# SAMA7G54D1GN2 register map
Vendor: Microchip Technology; Series: SAMA7G5; File version: 0
Registers are 32-bit, read-write, reset 0x0 unless marked. A register's access mark holds for its fields unless they carry their own. Offsets are from the block's base; [hi:lo] are bit positions; lines under a group give offsets from that group; {n}, {i} and the like mark numbered series; 'fields as' and 'values as' point back to an identical list.

## UDPHSA — IP_Name
Base 0xE0814000; register names take the prefix UDPHS_
Same registers: UDPHSB 0xE0818000
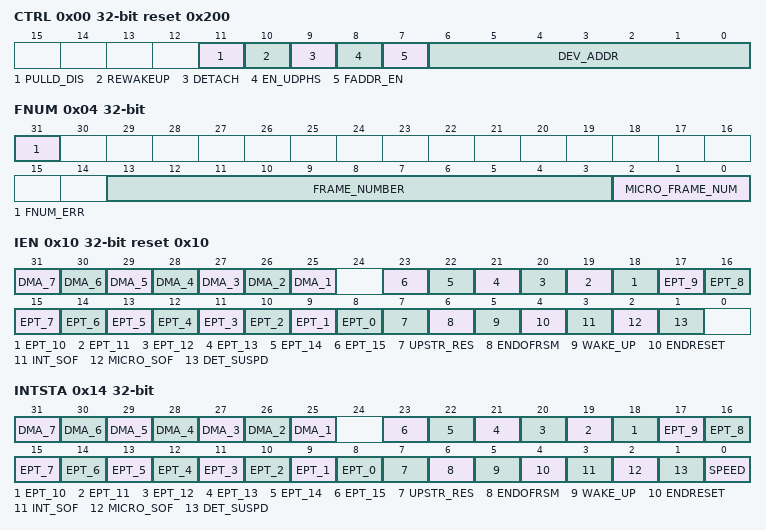
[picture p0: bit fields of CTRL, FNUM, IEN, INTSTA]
0x00 CTRL reset 0x200 — UDPHS Control Register
  [11] PULLD_DIS — Pulldown Disable (cleared upon USB reset)
  [10] REWAKEUP — Send Remote Wake-up (cleared upon USB reset)
    0=Remote Wake-up is disabled (read), or this bit has no effect (write); 1=Remote Wake-up is enabled (read), or this bit forces an external interrupt on the UDPHS controller for Remote Wake-up purposes
  [9] DETACH — Detach Command
    0=UDPHS is attached (read), or this bit pulls up the DP line (attach command) (write); 1=UDPHS is detached, UTMI transceiver is suspended (read), or this bit simulates a detach on the UDPHS line and forces the UTMI transceiver into Suspend state (Suspend M = 0) (write)
  [8] EN_UDPHS — UDPHS Enable
    0=UDPHS is disabled (read), or this bit disables and resets the UDPHS controller (write). Switch the UHPHS to UTMI.; 1=UDPHS is enabled (read), or this bit enables the UDPHS controller (write). Switch the UDPHS to UTMI.
  [7] FADDR_EN — Function Address Enable (cleared upon USB reset)
    0=The device is not in Address state (read), or only the default function address is used (write); 1=The device is in Address state (read), or this bit is set by the device firmware after a successful status phase of a SET_ADDRESS transaction (write). When set, the only address accepted by the UDPHS controller is the one stored in the UDPHS Address field. It will not be cleared afterwards by the device firmware. It is cleared by hardware on hardware reset, or when UDPHS bus reset is received.
  [6:0] DEV_ADDR — UDPHS Address (cleared upon USB reset)
0x04 FNUM ro — UDPHS Frame Number Register
  [31] FNUM_ERR — Frame Number CRC Error (cleared upon USB reset)
  [13:3] FRAME_NUMBER — Frame Number as defined in the Packet Field Formats (cleared upon USB reset)
  [2:0] MICRO_FRAME_NUM — Microframe Number (cleared upon USB reset)
0x10 IEN reset 0x10 — UDPHS Interrupt Enable Register
  [n+24] DMA_{n} (n=1..7) — DMA Channel {n} Interrupt Enable (cleared upon USB reset)
    0=Disable the interrupts for this channel; 1=Enable the interrupts for this channel
  [n+8] EPT_{n} (n=0..15) — Endpoint {n} Interrupt Enable (cleared upon USB reset)
    0=Disable the interrupts for this endpoint; 1=Enable the interrupts for this endpoint
  [7] UPSTR_RES — Upstream Resume Interrupt Enable (cleared upon USB reset)
    0=Disable Upstream Resume Interrupt; 1=Enable Upstream Resume Interrupt
  [6] ENDOFRSM — End Of Resume Interrupt Enable (cleared upon USB reset)
    0=Disable Resume Interrupt; 1=Enable Resume Interrupt
  [5] WAKE_UP — Wake Up CPU Interrupt Enable (cleared upon USB reset)
    0=Disable Wake-up CPU Interrupt; 1=Enable Wake-up CPU Interrupt
  [4] ENDRESET — End Of Reset Interrupt Enable (cleared upon USB reset)
    0=Disable End Of Reset Interrupt; 1=Enable End Of Reset Interrupt. Automatically enabled after USB reset.
  [3] INT_SOF — SOF Interrupt Enable (cleared upon USB reset)
    0=Disable SOF Interrupt; 1=Enable SOF Interrupt
  [2] MICRO_SOF — Micro-SOF Interrupt Enable (cleared upon USB reset)
    0=Disable Micro-SOF Interrupt; 1=Enable Micro-SOF Interrupt
  [1] DET_SUSPD — Suspend Interrupt Enable (cleared upon USB reset)
    0=Disable Suspend Interrupt; 1=Enable Suspend Interrupt
0x14 INTSTA ro — UDPHS Interrupt Status Register
  [n+24] DMA_{n} (n=1..7) — DMA Channel {n} Interrupt
    0=Reset when the UDPHS_DMASTATUSx interrupt source is cleared; 1=Set by hardware when an interrupt is triggered by the DMA Channelx and this endpoint interrupt is enabled by the DMA_x bit in UDPHS_IEN
  [n+8] EPT_{n} (n=0..15) — Endpoint {n} Interrupt (cleared upon USB reset)
    0=Reset when the UDPHS_EPTSTAx interrupt source is cleared; 1=Set by hardware when an interrupt is triggered by the UDPHS_EPTSTAx register and this endpoint interrupt is enabled by the EPT_x bit in UDPHS_IEN
  [7] UPSTR_RES — Upstream Resume Interrupt
    0=Cleared by setting the UPSTR_RES bit in UDPHS_CLRINT; 1=Set by hardware when the UDPHS controller is sending a resume signal called 'upstream resume'. This triggers a UDPHS interrupt when the UPSTR_RES bit is set in UDPHS_IEN.
  [6] ENDOFRSM — End Of Resume Interrupt
    0=Cleared by setting the ENDOFRSM bit in UDPHS_CLRINT; 1=Set by hardware when the UDPHS controller detects a good end of resume signal initiated by the host. This triggers a UDPHS interrupt when the ENDOFRSM bit is set in UDPHS_IEN.
  [5] WAKE_UP — Wake Up CPU Interrupt
    0=Cleared by setting the WAKE_UP bit in UDPHS_CLRINT; 1=Set by hardware when the UDPHS controller is in SUSPEND state and is re-activated by a filtered non-idle signal from the UDPHS line (not by an upstream resume). This triggers a UDPHS interrupt when the WAKE_UP bit is set in UDPHS_IEN register. When receiving this interrupt, the user has to enable the device controller clock prior to operation.
  [4] ENDRESET — End Of Reset Interrupt
    0=Cleared by setting the ENDRESET bit in UDPHS_CLRINT; 1=Set by hardware when an End Of Reset has been detected by the UDPHS controller. This triggers a UDPHS interrupt when the ENDRESET bit is set in UDPHS_IEN.
  [3] INT_SOF — Start Of Frame Interrupt
    0=Cleared by setting the INT_SOF bit in UDPHS_CLRINT; 1=Set by hardware when an UDPHS Start Of Frame PID (SOF) has been detected (every 1 ms) or synthesized by UDPHS. This triggers a UDPHS interrupt when the INT_SOF bit is set in UDPHS_IEN register. In case of detected SOF, in High Speed mode, the MICRO_FRAME_NUMBER field is cleared in UDPHS_FNUM register and the FRAME_NUMBER field is updated.
  [2] MICRO_SOF — Micro Start Of Frame Interrupt
    0=Cleared by setting the MICRO_SOF bit in UDPHS_CLRINT register; 1=Set by hardware when an UDPHS micro start of frame PID (SOF) has been detected (every 125 us) or synthesized by UDPHS. This triggers a UDPHS interrupt when the MICRO_SOF bit is set in UDPHS_IEN. In case of detected SOF, the MICRO_FRAME_NUM field in UDPHS_FNUM register is incremented and the FRAME_NUMBER field does not change.
  [1] DET_SUSPD — Suspend Interrupt
    0=Cleared by setting the DET_SUSPD bit in UDPHS_CLRINT register; 1=Set by hardware when a UDPHS Suspend (Idle bus for three frame periods, a J state for 3 ms) is detected. This triggers a UDPHS interrupt when the DET_SUSPD bit is set in UDPHS_IEN register.
  [0] SPEED — Speed Status
    0=Reset by hardware when the hardware is in Full Speed mode; 1=Set by hardware when the hardware is in High Speed mode
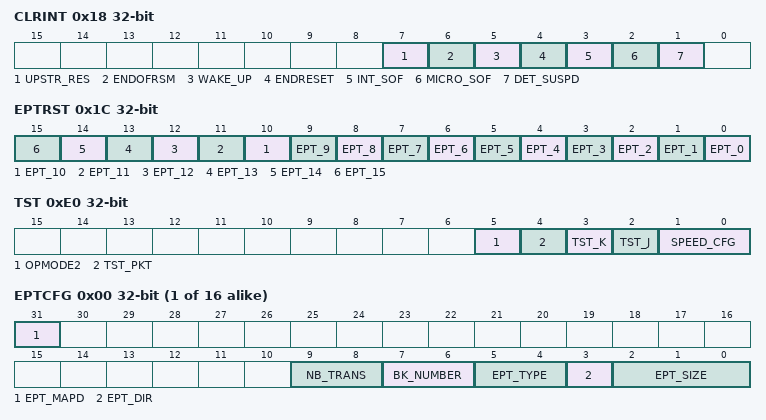
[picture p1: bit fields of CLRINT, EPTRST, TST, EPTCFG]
0x18 CLRINT wo — UDPHS Clear Interrupt Register
  [7] UPSTR_RES — Upstream Resume Interrupt Clear
    0=No effect; 1=Clear the UPSTR_RES bit in UDPHS_INTSTA
  [6] ENDOFRSM — End Of Resume Interrupt Clear
    0=No effect; 1=Clear the ENDOFRSM bit in UDPHS_INTSTA
  [5] WAKE_UP — Wake Up CPU Interrupt Clear
    0=No effect; 1=Clear the WAKE_UP bit in UDPHS_INTSTA
  [4] ENDRESET — End Of Reset Interrupt Clear
    0=No effect; 1=Clear the ENDRESET bit in UDPHS_INTSTA
  [3] INT_SOF — Start Of Frame Interrupt Clear
    0=No effect; 1=Clear the INT_SOF bit in UDPHS_INTSTA
  [2] MICRO_SOF — Micro Start Of Frame Interrupt Clear
    0=No effect; 1=Clear the MICRO_SOF bit in UDPHS_INTSTA
  [1] DET_SUSPD — Suspend Interrupt Clear
    0=No effect; 1=Clear the DET_SUSPD bit in UDPHS_INTSTA
0x1C EPTRST wo — UDPHS Endpoints Reset Register
  [all] fields
    0=No effect; 1=Reset the Endpointx state
  [n] EPT_{n} (n=0..15) — Endpoint {n} Reset
0xE0 TST — UDPHS Test Register
  [5] OPMODE2
    0=No effect; 1=Set to force the OpMode signal (UTMI interface) to '10', to disable the bit-stuffing and the NRZI encoding
  [4] TST_PKT — Test Packet Mode
    0=No effect; 1=Set to repetitively transmit the packet stored in the current bank. This enables the testing of rise and fall times, eye patterns, jitter, and any other dynamic waveform specifications.
  [3] TST_K — Test K Mode
    0=No effect; 1=Set to send the K state on the UDPHS line. This enables the testing of the high output drive level on the D- line.
  [2] TST_J — Test J Mode
    0=No effect; 1=Set to send the J state on the UDPHS line. This enables the testing of the high output drive level on the D+ line.
  [1:0] SPEED_CFG — Speed Configuration
    0=NORMAL (Normal mode: UDPHS is in Full Speed mode, ready to make a High Speed identification, if the host supports it and then to automatically switch to High Speed mode.); 2=HIGH_SPEED (Force High Speed: Set this value to force the hardware to work in High Speed mode. Only for debug or test purpose.); 3=FULL_SPEED (Force Full Speed: Set this value to force the hardware to work only in Full Speed mode. In this configuration, UDPHS will not respond to a High Speed reset handshake.)
{0x100+0x20*i} UDPHS_EPT[{i}] (i=0..15) group
  0x00 EPTCFG — UDPHS Endpoint Configuration Register
    [31] EPT_MAPD — Endpoint Mapped (cleared upon USB reset)
      0=The user should reprogram the register with correct values; 1=Set by hardware when the endpoint size (EPT_SIZE) and the number of banks (BK_NUMBER) are correct regarding:
    [9:8] NB_TRANS — Number Of Transactions per Microframe (cleared upon USB reset)
    [7:6] BK_NUMBER — Number of Banks (cleared upon USB reset)
      0=Zero bank, the endpoint is not mapped in memory; 1=One bank (bank 0); 2=Double bank (Ping-Pong: bank0/bank1); 3=Triple bank (bank0/bank1/bank2)
    [5:4] EPT_TYPE — Endpoint Type (cleared upon USB reset)
      0=CTRL8 (Control endpoint); 1=ISO (Isochronous endpoint); 2=BULK (Bulk endpoint); 3=INT (Interrupt endpoint)
    [3] EPT_DIR — Endpoint Direction (cleared upon USB reset)
      0=Clear this bit to configure OUT direction for Bulk, Interrupt and Isochronous endpoints; 1=Set this bit to configure IN direction for Bulk, Interrupt and Isochronous endpoints
    [2:0] EPT_SIZE — Endpoint Size (cleared upon USB reset)
      0=8 bytes; 1=16 bytes; 2=32 bytes; 3=64 bytes; 4=128 bytes; 5=256 bytes; 6=512 bytes; 7=1024 bytes
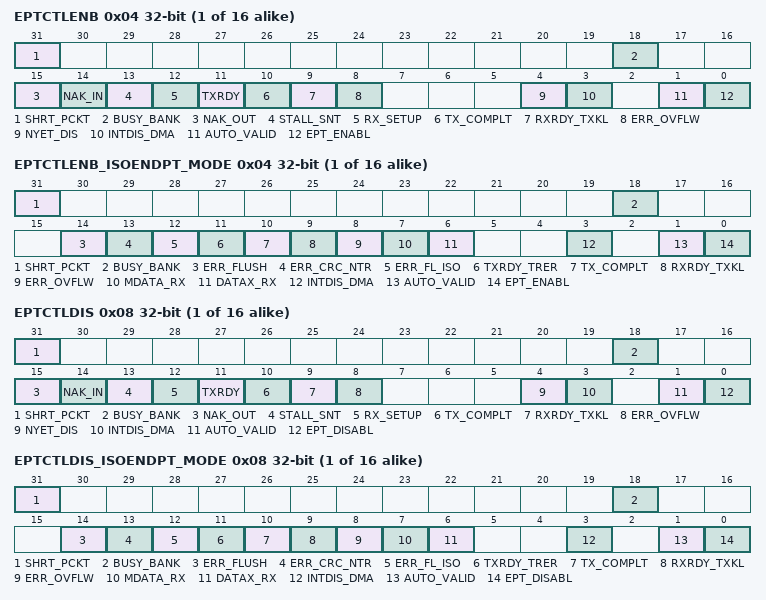
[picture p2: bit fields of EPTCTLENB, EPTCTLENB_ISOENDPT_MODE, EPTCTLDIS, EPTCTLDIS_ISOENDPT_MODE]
  0x04 EPTCTLENB wo — UDPHS Endpoint Control Enable Register
    [31] SHRT_PCKT — Short Packet Send/Short Packet Interrupt Enable
      0=No effect; 1=Enable Short Packet Interrupt
    [18] BUSY_BANK — Busy Bank Interrupt Enable
      0=No effect; 1=Enable Busy Bank Interrupt
    [15] NAK_OUT — NAKOUT Interrupt Enable
      0=No effect; 1=Enable NAKOUT Interrupt
    [14] NAK_IN — NAKIN Interrupt Enable
      0=No effect; 1=Enable NAKIN Interrupt
    [13] STALL_SNT — Stall Sent Interrupt Enable
      0=No effect; 1=Enable Stall Sent Interrupt
    [12] RX_SETUP — Received SETUP
      0=No effect; 1=Enable RX_SETUP Interrupt
    [11] TXRDY — TX Packet Ready Interrupt Enable
      0=No effect; 1=Enable TX Packet Ready/Transaction Error Interrupt
    [10] TX_COMPLT — Transmitted IN Data Complete Interrupt Enable
      0=No effect; 1=Enable Transmitted IN Data Complete Interrupt
    [9] RXRDY_TXKL — Received OUT Data Interrupt Enable
      0=No effect; 1=Enable Received OUT Data Interrupt
    [8] ERR_OVFLW — Overflow Error Interrupt Enable
      0=No effect; 1=Enable Overflow Error Interrupt
    [4] NYET_DIS — NYET Disable (Only for High Speed Bulk OUT endpoints)
      0=No effect; 1=Forces an ACK response to the next High Speed Bulk OUT transfer instead of a NYET response
    [3] INTDIS_DMA — Interrupts Disable DMA
      0=No effect; 1=If set, when an enabled endpoint-originated interrupt is triggered, the DMA request is disabled
    [1] AUTO_VALID — Packet Auto-Valid Enable
      0=No effect; 1=Enable this bit to automatically validate the current packet and switch to the next bank for both IN and OUT transfers
    [0] EPT_ENABL — Endpoint Enable
      0=No effect; 1=Enable endpoint according to the device configuration
  0x04 EPTCTLENB_ISOENDPT_MODE wo (alternate view of EPTCTLENB) — UDPHS Endpoint Control Enable Register
    [31] SHRT_PCKT — Short Packet Send/Short Packet Interrupt Enable
      0=No effect; 1=Enable Short Packet Interrupt
    [18] BUSY_BANK — Busy Bank Interrupt Enable
      0=No effect; 1=Enable Busy Bank Interrupt
    [14] ERR_FLUSH — Bank Flush Error Interrupt Enable
      0=No effect; 1=Enable Bank Flush Error Interrupt
    [13] ERR_CRC_NTR — ISO CRC Error/Number of Transaction Error Interrupt Enable
      0=No effect; 1=Enable Error CRC ISO/Error Number of Transaction Interrupt
    [12] ERR_FL_ISO — Error Flow Interrupt Enable
      0=No effect; 1=Enable Error Flow ISO Interrupt
    [11] TXRDY_TRER — TX Packet Ready/Transaction Error Interrupt Enable
      values as UDPHS_EPT[0].EPTCTLENB.TXRDY
    [10] TX_COMPLT — Transmitted IN Data Complete Interrupt Enable
      0=No effect; 1=Enable Transmitted IN Data Complete Interrupt
    [9] RXRDY_TXKL — Received OUT Data Interrupt Enable
      0=No effect; 1=Enable Received OUT Data Interrupt
    [8] ERR_OVFLW — Overflow Error Interrupt Enable
      0=No effect; 1=Enable Overflow Error Interrupt
    [7] MDATA_RX — MDATA Interrupt Enable (Only for high bandwidth Isochronous OUT endpoints)
      0=No effect; 1=Enable MDATA Interrupt
    [6] DATAX_RX — DATAx Interrupt Enable (Only for high bandwidth Isochronous OUT endpoints)
      0=No effect; 1=Enable DATAx Interrupt
    [3] INTDIS_DMA — Interrupts Disable DMA
      values as UDPHS_EPT[0].EPTCTLENB.INTDIS_DMA
    [1] AUTO_VALID — Packet Auto-Valid Enable
      values as UDPHS_EPT[0].EPTCTLENB.AUTO_VALID
    [0] EPT_ENABL — Endpoint Enable
      values as UDPHS_EPT[0].EPTCTLENB.EPT_ENABL
  0x08 EPTCTLDIS wo — UDPHS Endpoint Control Disable Register
    [31] SHRT_PCKT — Short Packet Interrupt Disable
      0=No effect; 1=Disable Short Packet Interrupt
    [18] BUSY_BANK — Busy Bank Interrupt Disable
      0=No effect; 1=Disable Busy Bank Interrupt
    [15] NAK_OUT — NAKOUT Interrupt Disable
      0=No effect; 1=Disable NAKOUT Interrupt
    [14] NAK_IN — NAKIN Interrupt Disable
      0=No effect; 1=Disable NAKIN Interrupt
    [13] STALL_SNT — Stall Sent Interrupt Disable
      0=No effect; 1=Disable Stall Sent Interrupt
    [12] RX_SETUP — Received SETUP Interrupt Disable
      0=No effect; 1=Disable RX_SETUP Interrupt
    [11] TXRDY — TX Packet Ready Interrupt Disable
      0=No effect; 1=Disable TX Packet Ready/Transaction Error Interrupt
    [10] TX_COMPLT — Transmitted IN Data Complete Interrupt Disable
      0=No effect; 1=Disable Transmitted IN Data Complete Interrupt
    [9] RXRDY_TXKL — Received OUT Data Interrupt Disable
      0=No effect; 1=Disable Received OUT Data Interrupt
    [8] ERR_OVFLW — Overflow Error Interrupt Disable
      0=No effect; 1=Disable Overflow Error Interrupt
    [4] NYET_DIS — NYET Enable (Only for High Speed Bulk OUT endpoints)
      0=No effect; 1=Let the hardware handle the handshake response for the High Speed Bulk OUT transfer
    [3] INTDIS_DMA — Interrupts Disable DMA
      0=No effect; 1=Disable the 'Interrupts Disable DMA'
    [1] AUTO_VALID — Packet Auto-Valid Disable
      0=No effect; 1=Disable this bit to not automatically validate the current packet
    [0] EPT_DISABL — Endpoint Disable
      0=No effect; 1=Disable endpoint
  0x08 EPTCTLDIS_ISOENDPT_MODE wo (alternate view of EPTCTLDIS) — UDPHS Endpoint Control Disable Register
    [31] SHRT_PCKT — Short Packet Interrupt Disable
      0=No effect; 1=Disable Short Packet Interrupt
    [18] BUSY_BANK — Busy Bank Interrupt Disable
      0=No effect; 1=Disable Busy Bank Interrupt
    [14] ERR_FLUSH — bank flush error Interrupt Disable
      0=No effect; 1=Disable Bank Flush Error Interrupt
    [13] ERR_CRC_NTR — ISO CRC Error/Number of Transaction Error Interrupt Disable
      0=No effect; 1=Disable Error CRC ISO/Error Number of Transaction Interrupt
    [12] ERR_FL_ISO — Error Flow Interrupt Disable
      0=No effect; 1=Disable Error Flow ISO Interrupt
    [11] TXRDY_TRER — TX Packet Ready/Transaction Error Interrupt Disable
      values as UDPHS_EPT[0].EPTCTLDIS.TXRDY
    [10] TX_COMPLT — Transmitted IN Data Complete Interrupt Disable
      values as UDPHS_EPT[0].EPTCTLDIS.TX_COMPLT
    [9] RXRDY_TXKL — Received OUT Data Interrupt Disable
      0=No effect; 1=Disable Received OUT Data Interrupt
    [8] ERR_OVFLW — Overflow Error Interrupt Disable
      0=No effect; 1=Disable Overflow Error Interrupt
    [7] MDATA_RX — MDATA Interrupt Disable (Only for High Bandwidth Isochronous OUT endpoints)
      0=No effect; 1=Disable MDATA Interrupt
    [6] DATAX_RX — DATAx Interrupt Disable (Only for High Bandwidth Isochronous OUT endpoints)
      0=No effect; 1=Disable DATAx Interrupt
    [3] INTDIS_DMA — Interrupts Disable DMA
      0=No effect; 1=Disable the 'Interrupts Disable DMA'
    [1] AUTO_VALID — Packet Auto-Valid Disable
      values as UDPHS_EPT[0].EPTCTLDIS.AUTO_VALID
    [0] EPT_DISABL — Endpoint Disable
      0=No effect; 1=Disable endpoint
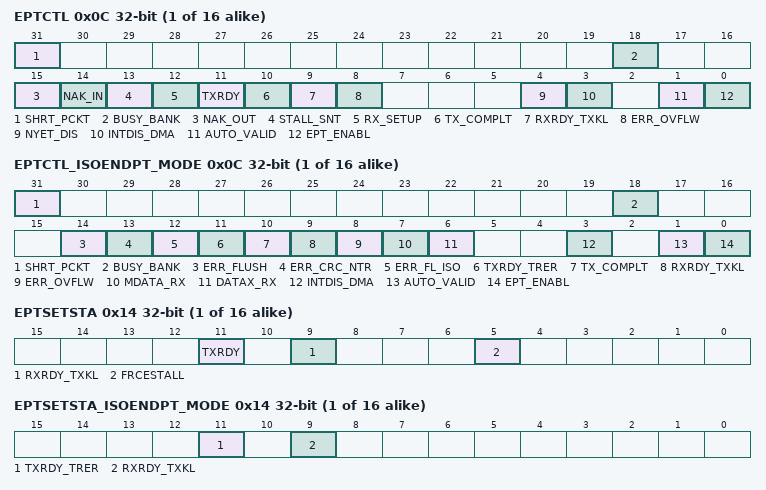
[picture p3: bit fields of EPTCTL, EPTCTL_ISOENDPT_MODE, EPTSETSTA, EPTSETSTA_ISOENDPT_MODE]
  0x0C EPTCTL ro — UDPHS Endpoint Control Register
    [31] SHRT_PCKT — Short Packet Interrupt Enabled (cleared upon USB reset)
      0=Short Packet Interrupt is masked; 1=Short Packet Interrupt is enabled
    [18] BUSY_BANK — Busy Bank Interrupt Enabled (cleared upon USB reset)
      0=BUSY_BANK Interrupt is masked; 1=BUSY_BANK Interrupt is enabled
    [15] NAK_OUT — NAKOUT Interrupt Enabled (cleared upon USB reset)
      0=NAKOUT Interrupt is masked; 1=NAKOUT Interrupt is enabled
    [14] NAK_IN — NAKIN Interrupt Enabled (cleared upon USB reset)
      0=NAKIN Interrupt is masked; 1=NAKIN Interrupt is enabled
    [13] STALL_SNT — Stall Sent Interrupt Enabled (cleared upon USB reset)
      0=Stall Sent Interrupt is masked; 1=Stall Sent Interrupt is enabled
    [12] RX_SETUP — Received SETUP Interrupt Enabled (cleared upon USB reset)
      0=Received SETUP is masked; 1=Received SETUP is enabled
    [11] TXRDY — TX Packet Ready Interrupt Enabled (cleared upon USB reset)
      0=TX Packet Ready Interrupt is masked; 1=TX Packet Ready Interrupt is enabled
    [10] TX_COMPLT — Transmitted IN Data Complete Interrupt Enabled (cleared upon USB reset)
      0=Transmitted IN Data Complete Interrupt is masked; 1=Transmitted IN Data Complete Interrupt is enabled
    [9] RXRDY_TXKL — Received OUT Data Interrupt Enabled (cleared upon USB reset)
      0=Received OUT Data Interrupt is masked; 1=Received OUT Data Interrupt is enabled
    [8] ERR_OVFLW — Overflow Error Interrupt Enabled (cleared upon USB reset)
      0=Overflow Error Interrupt is masked; 1=Overflow Error Interrupt is enabled
    [4] NYET_DIS — NYET Disable (Only for High Speed Bulk OUT Endpoints) (cleared upon USB reset)
      0=Lets the hardware handle the handshake response for the High Speed Bulk OUT transfer; 1=Forces an ACK response to the next High Speed Bulk OUT transfer instead of a NYET response
    [3] INTDIS_DMA — Interrupt Disables DMA (cleared upon USB reset)
    [1] AUTO_VALID — Packet Auto-Valid Enabled (Not for CONTROL Endpoints) (cleared upon USB reset)
    [0] EPT_ENABL — Endpoint Enable (cleared upon USB reset)
      0=The endpoint is disabled according to the device configuration. Endpoint 0 should always be enabled after a hardware or UDPHS bus reset and participate in the device configuration.; 1=The endpoint is enabled according to the device configuration
  0x0C EPTCTL_ISOENDPT_MODE ro (alternate view of EPTCTL) — UDPHS Endpoint Control Register
    [31] SHRT_PCKT — Short Packet Interrupt Enabled (cleared upon USB reset)
      values as UDPHS_EPT[0].EPTCTL.SHRT_PCKT
    [18] BUSY_BANK — Busy Bank Interrupt Enabled (cleared upon USB reset)
      values as UDPHS_EPT[0].EPTCTL.BUSY_BANK
    [14] ERR_FLUSH — Bank Flush Error Interrupt Enabled (cleared upon USB reset)
      0=Bank Flush Error Interrupt is masked; 1=Bank Flush Error Interrupt is enabled
    [13] ERR_CRC_NTR — ISO CRC Error/Number of Transaction Error Interrupt Enabled (cleared upon USB reset)
      0=ISO CRC error/number of Transaction Error Interrupt is masked; 1=ISO CRC error/number of Transaction Error Interrupt is enabled
    [12] ERR_FL_ISO — Error Flow Interrupt Enabled (cleared upon USB reset)
      0=Error Flow Interrupt is masked; 1=Error Flow Interrupt is enabled
    [11] TXRDY_TRER — TX Packet Ready/Transaction Error Interrupt Enabled (cleared upon USB reset)
      0=TX Packet Ready/Transaction Error Interrupt is masked; 1=TX Packet Ready/Transaction Error Interrupt is enabled
    [10] TX_COMPLT — Transmitted IN Data Complete Interrupt Enabled (cleared upon USB reset)
      values as UDPHS_EPT[0].EPTCTL.TX_COMPLT
    [9] RXRDY_TXKL — Received OUT Data Interrupt Enabled (cleared upon USB reset)
      values as UDPHS_EPT[0].EPTCTL.RXRDY_TXKL
    [8] ERR_OVFLW — Overflow Error Interrupt Enabled (cleared upon USB reset)
      values as UDPHS_EPT[0].EPTCTL.ERR_OVFLW
    [7] MDATA_RX — MDATA Interrupt Enabled (Only for High Bandwidth Isochronous OUT endpoints) (cleared upon USB reset)
      0=No effect; 1=Send an interrupt when an MDATA packet has been received and so at least one packet of the microframe data payload has been received
    [6] DATAX_RX — DATAx Interrupt Enabled (Only for High Bandwidth Isochronous OUT endpoints) (cleared upon USB reset)
      0=No effect; 1=Send an interrupt when a DATA2, DATA1 or DATA0 packet has been received meaning the whole microframe data payload has been received
    [3] INTDIS_DMA — Interrupt Disables DMA (cleared upon USB reset)
    [1] AUTO_VALID — Packet Auto-Valid Enabled (cleared upon USB reset)
    [0] EPT_ENABL — Endpoint Enable (cleared upon USB reset)
      values as UDPHS_EPT[0].EPTCTL.EPT_ENABL
  0x14 EPTSETSTA wo — UDPHS Endpoint Set Status Register
    [11] TXRDY — TX Packet Ready Set
      0=No effect; 1=Set this bit after a packet has been written into the endpoint FIFO for IN data transfers
    [9] RXRDY_TXKL — KILL Bank Set (for IN Endpoint)
      0=No effect; 1=Kill the last written bank
    [5] FRCESTALL — Stall Handshake Request Set
      0=No effect; 1=Set this bit to request a STALL answer to the host for the next handshake
  0x14 EPTSETSTA_ISOENDPT_MODE wo (alternate view of EPTSETSTA) — UDPHS Endpoint Set Status Register
    [11] TXRDY_TRER — TX Packet Ready Set
      values as UDPHS_EPT[0].EPTSETSTA.TXRDY
    [9] RXRDY_TXKL — KILL Bank Set (for IN Endpoint)
      0=No effect; 1=Kill the last written bank
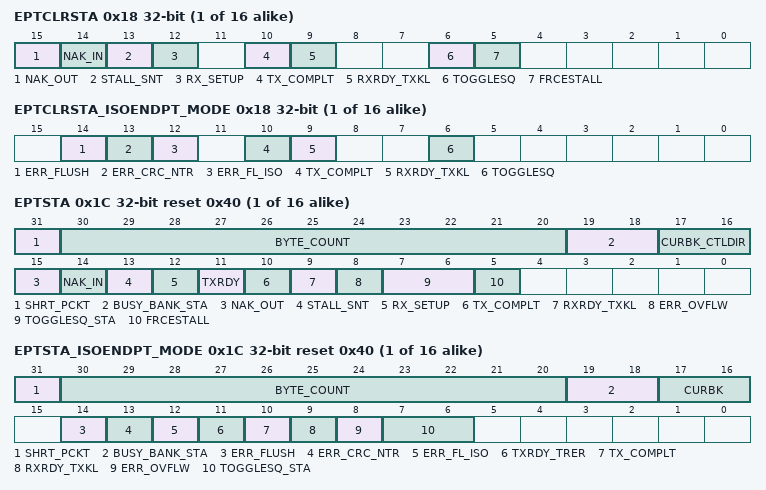
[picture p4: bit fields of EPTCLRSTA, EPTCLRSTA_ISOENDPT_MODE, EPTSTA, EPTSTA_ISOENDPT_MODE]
  0x18 EPTCLRSTA wo — UDPHS Endpoint Clear Status Register
    [15] NAK_OUT — NAKOUT Clear
      0=No effect; 1=Clear the NAK_OUT flag of UDPHS_EPTSTAx
    [14] NAK_IN — NAKIN Clear
      0=No effect; 1=Clear the NAK_IN flags of UDPHS_EPTSTAx
    [13] STALL_SNT — Stall Sent Clear
      0=No effect; 1=Clear the STALL_SNT flags of UDPHS_EPTSTAx
    [12] RX_SETUP — Received SETUP Clear
      0=No effect; 1=Clear the RX_SETUP flags of UDPHS_EPTSTAx
    [10] TX_COMPLT — Transmitted IN Data Complete Clear
      0=No effect; 1=Clear the TX_COMPLT flag of UDPHS_EPTSTAx
    [9] RXRDY_TXKL — Received OUT Data Clear
      0=No effect; 1=Clear the RXRDY_TXKL flag of UDPHS_EPTSTAx
    [6] TOGGLESQ — Data Toggle Clear
      0=No effect; 1=Clear the PID data of the current bank
    [5] FRCESTALL — Stall Handshake Request Clear
      0=No effect; 1=Clear the STALL request. The next packets from host will not be STALLed.
  0x18 EPTCLRSTA_ISOENDPT_MODE wo (alternate view of EPTCLRSTA) — UDPHS Endpoint Clear Status Register
    [14] ERR_FLUSH — Bank Flush Error Clear
      0=No effect; 1=Clear the ERR_FLUSH flags of UDPHS_EPTSTAx
    [13] ERR_CRC_NTR — Number of Transaction Error Clear
      0=No effect; 1=Clear the ERR_CRC_NTR flags of UDPHS_EPTSTAx
    [12] ERR_FL_ISO — Error Flow Clear
      0=No effect; 1=Clear the ERR_FL_ISO flags of UDPHS_EPTSTAx
    [10] TX_COMPLT — Transmitted IN Data Complete Clear
      0=No effect; 1=Clear the TX_COMPLT flag of UDPHS_EPTSTAx
    [9] RXRDY_TXKL — Received OUT Data Clear
      0=No effect; 1=Clear the RXRDY_TXKL flag of UDPHS_EPTSTAx
    [6] TOGGLESQ — Data Toggle Clear
      0=No effect; 1=Clear the PID data of the current bank
  0x1C EPTSTA ro reset 0x40 — UDPHS Endpoint Status Register
    [31] SHRT_PCKT — Short Packet (cleared upon USB reset)
    [30:20] BYTE_COUNT — UDPHS Byte Count (cleared upon USB reset)
    [19:18] BUSY_BANK_STA — Busy Bank Number (cleared upon USB reset)
      0=0BUSYBANK (All banks are free); 1=1BUSYBANK; 2=2BUSYBANKS; 3=3BUSYBANKS
    [17:16] CURBK_CTLDIR — Current Bank/Control Direction (cleared upon USB reset)
      0=BANK0 (Control Direction (for Control endpoint only): A Control Write is requested by the Host. Current Bank (not relevant for Control endpoint): Bank 0 (or single bank).); 1=BANK1 (Control Direction (for Control endpoint only): A Control Read is requested by the Host. Current Bank (not relevant for Control endpoint): Bank 1.); 2=BANK2 (Current Bank (not relevant for Control endpoint): Bank 2.)
    [15] NAK_OUT — NAK OUT (cleared upon USB reset)
    [14] NAK_IN — NAK IN (cleared upon USB reset)
    [13] STALL_SNT — Stall Sent (cleared upon USB reset)
    [12] RX_SETUP — Received SETUP (cleared upon USB reset)
    [11] TXRDY — TX Packet Ready (cleared upon USB reset)
    [10] TX_COMPLT — Transmitted IN Data Complete (cleared upon USB reset)
    [9] RXRDY_TXKL — Received OUT Data/KILL Bank (cleared upon USB reset)
    [8] ERR_OVFLW — Overflow Error (cleared upon USB reset)
    [7:6] TOGGLESQ_STA — Toggle Sequencing (cleared upon USB reset)
      0=DATA0; 1=DATA1
    [5] FRCESTALL — Stall Handshake Request (cleared upon USB reset)
      0=No effect; 1=If set a STALL answer will be done to the host for the next handshake
  0x1C EPTSTA_ISOENDPT_MODE ro reset 0x40 (alternate view of EPTSTA) — UDPHS Endpoint Status Register
    [31] SHRT_PCKT — Short Packet (cleared upon USB reset)
    [30:20] BYTE_COUNT — UDPHS Byte Count (cleared upon USB reset)
    [19:18] BUSY_BANK_STA — Busy Bank Number (cleared upon USB reset)
      values as UDPHS_EPT[0].EPTSTA.BUSY_BANK_STA
    [17:16] CURBK — Current Bank (cleared upon USB reset)
      0=BANK0 (Bank 0 (or single bank)); 1=BANK1; 2=BANK2
    [14] ERR_FLUSH — Bank Flush Error (cleared upon USB reset)
    [13] ERR_CRC_NTR — CRC ISO Error/Number of Transaction Error (cleared upon USB reset)
    [12] ERR_FL_ISO — Error Flow (cleared upon USB reset)
    [11] TXRDY_TRER — TX Packet Ready/Transaction Error (cleared upon USB reset)
    [10] TX_COMPLT — Transmitted IN Data Complete (cleared upon USB reset)
    [9] RXRDY_TXKL — Received OUT Data/KILL Bank (cleared upon USB reset)
    [8] ERR_OVFLW — Overflow Error (cleared upon USB reset)
    [7:6] TOGGLESQ_STA — Toggle Sequencing (cleared upon USB reset)
      0=DATA0; 1=DATA1; 2=DATA2 (Data2 (only for High Bandwidth Isochronous Endpoint)); 3=MDATA (MData (only for High Bandwidth Isochronous Endpoint))
{0x300+0x10*i} UDPHS_DMA{i} (i=1..7) group
  0x00 DMANXTDSC — UDPHS DMA Next Descriptor Address Register
    [31:0] NXT_DSC_ADD — Next Descriptor Address
  0x04 DMAADDRESS — UDPHS DMA Channel Address Register
    [31:0] BUFF_ADD — Buffer Address
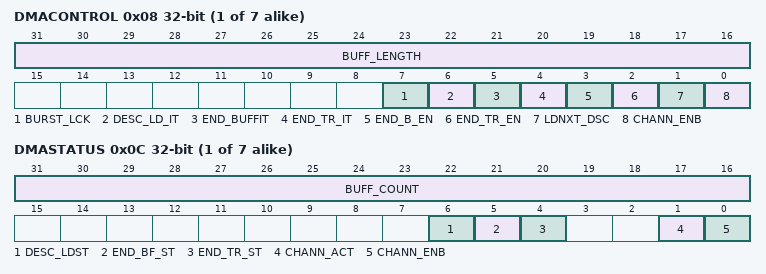
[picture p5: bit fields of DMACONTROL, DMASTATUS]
  0x08 DMACONTROL — UDPHS DMA Channel Control Register
    [31:16] BUFF_LENGTH — Buffer Byte Length (Write-only)
    [7] BURST_LCK — Burst Lock Enable
      0=The DMA never locks bus access; 1=USB packets system bus data bursts are locked for maximum optimization of the bus bandwidth usage and maximization of fly-by system bus burst duration
    [6] DESC_LD_IT — Descriptor Loaded Interrupt Enable
      0=UDPHS_DMASTATUSx/DESC_LDST rising will not trigger any interrupt; 1=An interrupt is generated when a descriptor has been loaded from the bus
    [5] END_BUFFIT — End of Buffer Interrupt Enable
      0=UDPHS_DMA_STATUSx/END_BF_ST rising will not trigger any interrupt; 1=An interrupt is generated when the UDPHS_DMASTATUSx register BUFF_COUNT reaches zero
    [4] END_TR_IT — End of Transfer Interrupt Enable
      0=UDPHS device initiated buffer transfer completion will not trigger any interrupt at UDPHS_STATUSx/END_TR_ST rising; 1=An interrupt is sent after the buffer transfer is complete, if the UDPHS device has ended the buffer transfer
    [3] END_B_EN — End of Buffer Enable (Control)
      0=DMA Buffer End has no impact on USB packet transfer; 1=Endpoint can validate the packet (according to the values programmed in the UDPHS_EPTCTLx register AUTO_VALID and SHRT_PCKT fields) at DMA Buffer End, i.e., when the UDPHS_DMASTATUS register BUFF_COUNT reaches 0
    [2] END_TR_EN — End of Transfer Enable (Control)
      0=USB end of transfer is ignored; 1=UDPHS device can put an end to the current buffer transfer
    [1] LDNXT_DSC — Load Next Channel Transfer Descriptor Enable (Command)
      0=No channel register is loaded after the end of the channel transfer; 1=The channel controller loads the next descriptor after the end of the current transfer, i.e., when the UDPHS_DMASTATUS/CHANN_ENB bit is reset
    [0] CHANN_ENB — (Channel Enable Command)
      0=DMA channel is disabled at and no transfer will occur upon request. This bit is also cleared by hardware when the channel source bus is disabled at end of buffer.; 1=UDPHS_DMASTATUS register CHANN_ENB bit will be set, thus enabling DMA channel data transfer. Then any pending request will start the transfer. This may be used to start or resume any requested transfer.
  0x0C DMASTATUS — UDPHS DMA Channel Status Register
    [31:16] BUFF_COUNT — Buffer Byte Count
    [6] DESC_LDST — Descriptor Loaded Status
      0=Cleared automatically when read by software; 1=Set by hardware when a descriptor has been loaded from the system bus
    [5] END_BF_ST — End of Channel Buffer Status
      0=Cleared automatically when read by software; 1=Set by hardware when the BUFF_COUNT countdown reaches zero
    [4] END_TR_ST — End of Channel Transfer Status
      0=Cleared automatically when read by software; 1=Set by hardware when the last packet transfer is complete, if the UDPHS device has ended the transfer
    [1] CHANN_ACT — Channel Active Status
      0=The DMA channel is no longer trying to source the packet data; 1=The DMA channel is currently trying to source packet data, i.e., selected as the highest-priority requesting channel
    [0] CHANN_ENB — Channel Enable Status
      0=The DMA channel no longer transfers data, and may load the next descriptor if the UDPHS_DMACONTROLx register LDNXT_DSC bit is set; 1=The DMA channel is currently enabled and transfers data upon request
